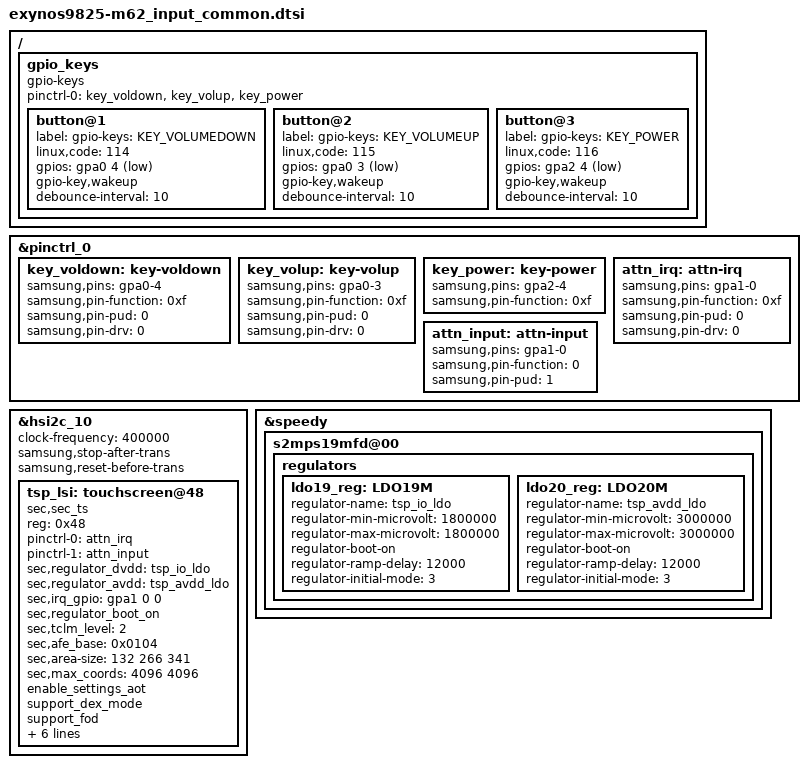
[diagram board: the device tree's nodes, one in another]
/*
 * SAMSUNG EXYNOS9825 board device tree source
 *
 * Copyright (c) 2018 Samsung Electronics Co., Ltd.
 *		http://www.samsung.com
 *
 * This program is free software; you can redistribute it and/or modify
 * it under the terms of the GNU General Public License version 2 as
 * published by the Free Software Foundation.
*/

#include "exynos9820-inputbooster.dtsi"

/ {
	fragment@model {
		target-path = "/";
		__overlay__ {
			gpio_keys {
				status = "okay";
				compatible = "gpio-keys";
				pinctrl-names = "default";
				pinctrl-0 = <&key_voldown &key_volup &key_power>;
				button@1 {
					label = "gpio-keys: KEY_VOLUMEDOWN";
					linux,code = <114>;
					gpios = <&gpa0 4 0xf>;
					gpio-key,wakeup;
					debounce-interval = <10>;
				};
				button@2 {
					label = "gpio-keys: KEY_VOLUMEUP";
					linux,code = <115>;
					gpios = <&gpa0 3 0xf>;
					gpio-key,wakeup;
					debounce-interval = <10>;
				};
				button@3 {
					label = "gpio-keys: KEY_POWER";
					linux,code = <116>;
					gpios = <&gpa2 4 0xf>;
					gpio-key,wakeup;
					debounce-interval = <10>;
				};
			};
		};
	};
};

&pinctrl_0 {
	key_voldown: key-voldown {
		samsung,pins = "gpa0-4";
		samsung,pin-function = <0xf>;
		samsung,pin-pud = <0>;
		samsung,pin-drv = <0>;
	};

	key_volup: key-volup {
		samsung,pins = "gpa0-3";
		samsung,pin-function = <0xf>;
		samsung,pin-pud = <0>;
		samsung,pin-drv = <0>;
	};

	key_power: key-power {
		samsung,pins = "gpa2-4";
		samsung,pin-function = <0xf>;
	};

	attn_irq: attn-irq {
		samsung,pins = "gpa1-0";
		samsung,pin-function = <0xf>;
		samsung,pin-pud = <0>;
		samsung,pin-drv = <0>;
	};

	attn_input: attn-input {
		samsung,pins = "gpa1-0";
		samsung,pin-function = <0>;
		samsung,pin-pud = <1>;
	};
};

&hsi2c_10 {
	#address-cells = <1>;
	#size-cells = <0>;
	status = "okay";
	clock-frequency = <400000>;
	samsung,stop-after-trans;	/* LSI IC ONLY */
	samsung,reset-before-trans;
	tsp_lsi: touchscreen@48 {
		status = "ok";
		compatible = "sec,sec_ts";
		reg = <0x48>;
		pinctrl-names = "on_state", "off_state";
		pinctrl-0 = <&attn_irq>;
		pinctrl-1 = <&attn_input>;
		sec,regulator_dvdd = "tsp_io_ldo";
		sec,regulator_avdd = "tsp_avdd_ldo";
		sec,irq_gpio = <&gpa1 0 0>;
		sec,regulator_boot_on;
		sec,tclm_level = <2>;
		sec,afe_base = <0x0104>;
		sec,area-size = <132 266 341>; /* indicator: 24dp navigator:48dp edge:60px dpi=320 */
		sec,max_coords = <4096 4096>; /* x y */

		enable_settings_aot;
		support_dex_mode;
		support_fod;
		support_mis_calibration_test;
		support_ear_detect_mode;
//		sync-reportrate-120;
		support_open_short_test;
		override_use_sponge;

		/* This part is for firmware */
		sec,project_name = "F62", "E625";
		sec,firmware_name = "tsp_sec/y771_f62.bin";
//		sec,bringup = <3>;
	};
};

&speedy {
	s2mps19mfd@00 {
		regulators {
			ldo19_reg: LDO19M {
				regulator-name = "tsp_io_ldo";
				regulator-min-microvolt = <1800000>;
				regulator-max-microvolt = <1800000>;
				regulator-boot-on;
				regulator-ramp-delay = <12000>;
				regulator-initial-mode = <3>;
			};

			ldo20_reg: LDO20M {
				regulator-name = "tsp_avdd_ldo";
				regulator-min-microvolt = <3000000>;
				regulator-max-microvolt = <3000000>;
				regulator-boot-on;
				regulator-ramp-delay = <12000>;
				regulator-initial-mode = <3>;
			};		
		};
	};
};

